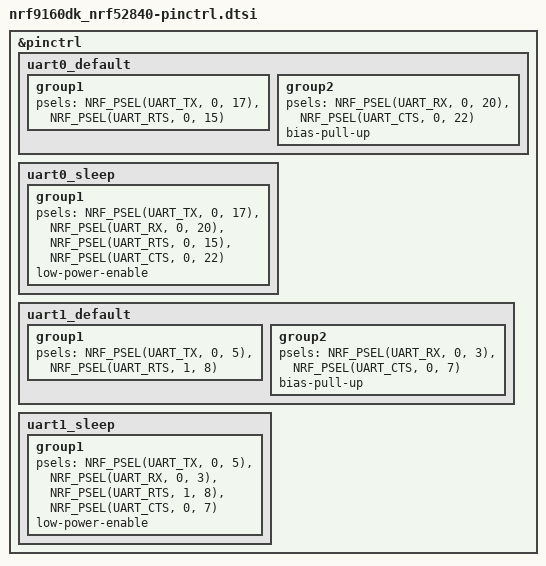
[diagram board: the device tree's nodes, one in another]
/*
 * Copyright (c) 2022 Nordic Semiconductor
 * SPDX-License-Identifier: Apache-2.0
 */

&pinctrl {
	uart0_default: uart0_default {
		group1 {
			psels = <NRF_PSEL(UART_TX, 0, 17)>, // <&interface_to_nrf9160 0 0.17>
				<NRF_PSEL(UART_RTS, 0, 15)>;    // <&interface_to_nrf9160 2 0.19>
		};
		group2 {
			psels = <NRF_PSEL(UART_RX, 0, 20)>, // <&interface_to_nrf9160 1 0.18>
				<NRF_PSEL(UART_CTS, 0, 22)>;    // <&interface_to_nrf9160 3 0.21>
			bias-pull-up;
		};
	};

	uart0_sleep: uart0_sleep {
		group1 {
			psels = <NRF_PSEL(UART_TX, 0, 17)>, // <&interface_to_nrf9160 0 0.17>
				<NRF_PSEL(UART_RX, 0, 20)>,     // <&interface_to_nrf9160 1 0.18>
				<NRF_PSEL(UART_RTS, 0, 15)>,    // <&interface_to_nrf9160 2 0.19>
				<NRF_PSEL(UART_CTS, 0, 22)>;    // <&interface_to_nrf9160 3 0.21>
			low-power-enable;
		};
	};

	uart1_default: uart1_default {
		group1 {
			psels = <NRF_PSEL(UART_TX, 0, 5)>,
				<NRF_PSEL(UART_RTS, 1, 8)>;
		};
		group2 {
			psels = <NRF_PSEL(UART_RX, 0, 3)>,
				<NRF_PSEL(UART_CTS, 0, 7)>;
			bias-pull-up;
		};
	};

	uart1_sleep: uart1_sleep {
		group1 {
			psels = <NRF_PSEL(UART_TX, 0, 5)>,
				<NRF_PSEL(UART_RX, 0, 3)>,
				<NRF_PSEL(UART_RTS, 1, 8)>,
				<NRF_PSEL(UART_CTS, 0, 7)>;
			low-power-enable;
		};
	};

};
